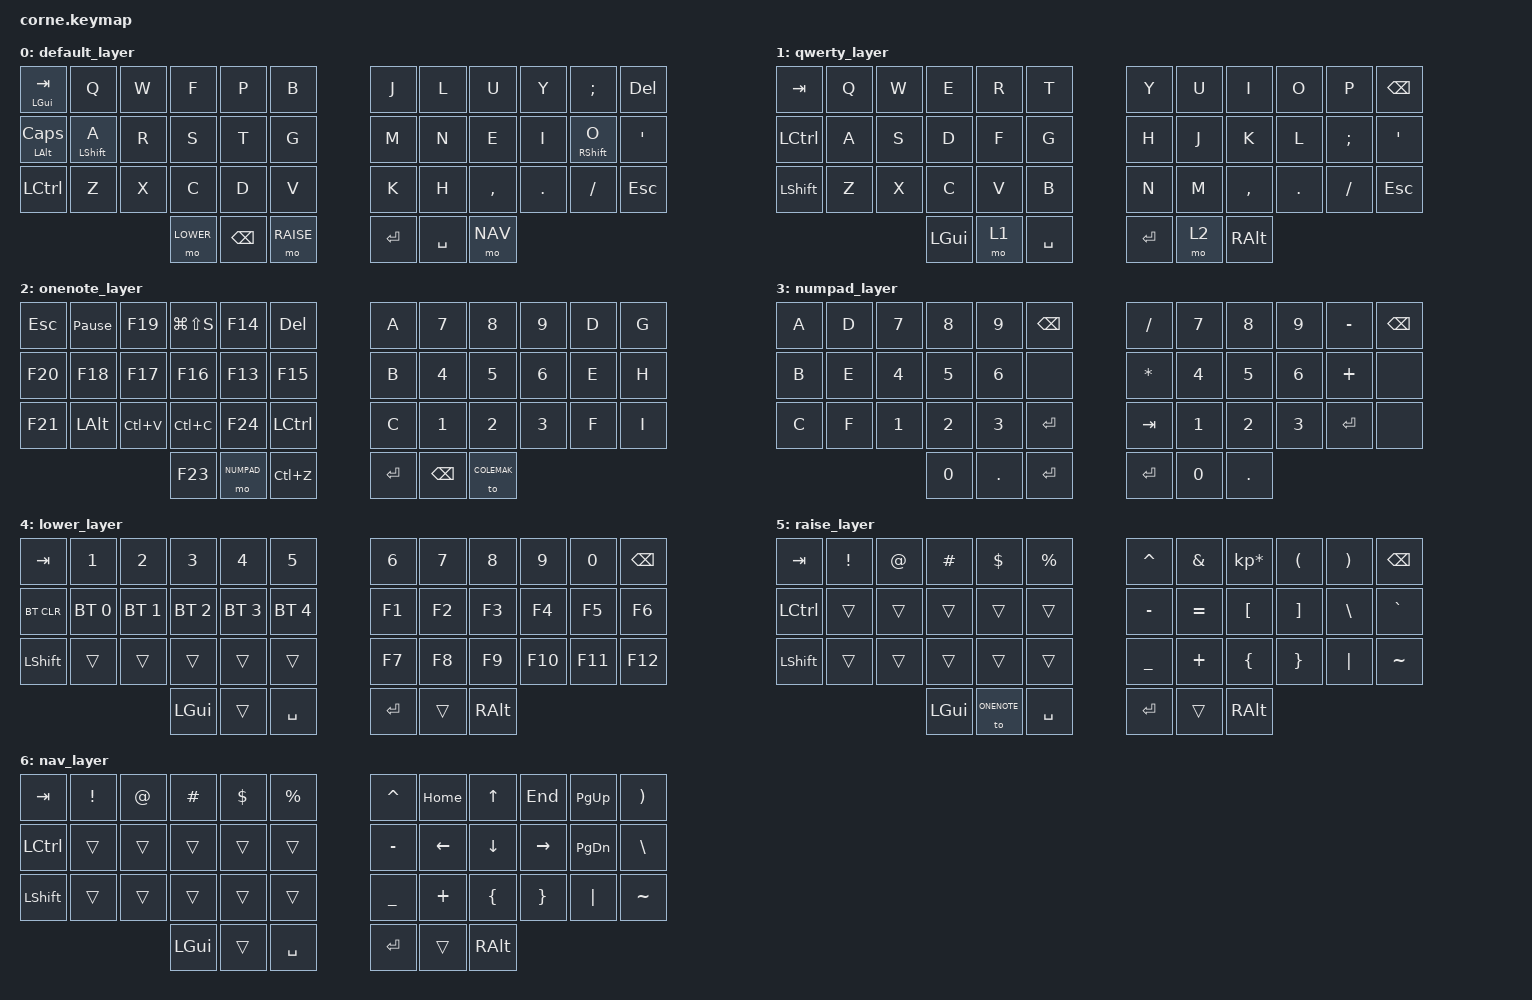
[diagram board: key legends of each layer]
/*
 * Copyright (c) 2020 The ZMK Contributors
 *
 * SPDX-License-Identifier: MIT
 */

#include <behaviors.dtsi>
#include <dt-bindings/zmk/keys.h>
#include <dt-bindings/zmk/bt.h>

#define COLEMAK 0
#define QWERTY  1
#define ONENOTE 2
#define NUMPAD  3
#define LOWER   4
#define RAISE   5
#define NAV		6



/ {
    combos {
        compatible = "zmk,combos";
		
		combo_colemak {
            timeout-ms = <50>;
            key-positions = <5 6 29 30>;
            bindings = <&to COLEMAK>;
        };
		
        combo_onenote {
            timeout-ms = <25>;
            key-positions = <0 24>;
            bindings = <&to ONENOTE>;
        };
		
		combo_qwerty {
			timeout-ms = <10>;
            key-positions = <1 10 25 34>;
            bindings = <&tog QWERTY>;
			layers = <COLEMAK>;
		};
		
		combo_numpad_L {
			timeout-ms = <25>;
            key-positions = <5 17>;
            bindings = <&tog NUMPAD>;
		};
		
		combo_numpad_R {
			timeout-ms = <25>;
            key-positions = <6 18>;
            bindings = <&tog NUMPAD>;
		};
    };
};

/ {
	behaviors {
		hm: homerow_mods {
			compatible = "zmk,behavior-hold-tap";
			label = "HOMEROW_MODS";
			#binding-cells = <2>;
			tapping-term-ms = <180>;
			quick_tap_ms = <125>;
			flavor = "balanced";
			bindings = <&kp>, <&kp>;
		};
	};

	keymap {
		compatible = "zmk,keymap";

		default_layer {
// -----------------------------------------------------------------------------------------
// | GUI/TAB  |    Q   |  W  |  F  |  P   |  B  |	|  J  |  L  |  U  |  Y  |   ;    | DEL |
// | ALT/CAPS | SHFT/A |  R  |  S  |  T   |  G  |	|  M  |  N  |  E  |  I  | SHFT/O |  '  |
// | CTRL     |    Z   |  X  |  C  |  D   |  V  |	|  K  |  H  |  ,  |  .  |   /    | ESC |
// 						     | LWR | BKSP | RSE |	| ENT | SPC | NAV |
			bindings = <
   &hm LGUI TAB  &kp Q 	     &kp W &kp F     &kp P    &kp B     &kp J   &kp L     &kp U     &kp Y   &kp SEMI	&kp DEL
   &hm LALT CAPS &hm LSHFT A &kp R &kp S     &kp T    &kp G     &kp M   &kp N     &kp E     &kp I   &hm RSHFT O &kp SQT
   &kp LCTRL     &kp Z		 &kp X &kp C	 &kp D    &kp V	    &kp K   &kp H     &kp COMMA &kp DOT &kp FSLH	&kp ESC
								   &mo LOWER &kp BSPC &mo RAISE &kp RET &kp SPACE &mo NAV
			>;
		};
				
		qwerty_layer {
// -----------------------------------------------------------------------------------------
// |  TAB |  Q  |  W  |  E  |  R  |  T  |   |  Y  |  U   |  I  |  O  |  P  | BKSP |
// | CTRL |  A  |  S  |  D  |  F  |  G  |   |  H  |  J   |  K  |  L  |  ;  |  '   |
// | SHFT |  Z  |  X  |  C  |  V  |  B  |   |  N  |  M   |  ,  |  .  |  /  | ESC  |
//                    | GUI | LWR | SPC |   | ENT | RSE  | ALT |
			bindings = <
   &kp TAB   &kp Q &kp W &kp E &kp R &kp T   &kp Y &kp U  &kp I     &kp O   &kp P    &kp BSPC
   &kp LCTRL &kp A &kp S &kp D &kp F &kp G   &kp H &kp J  &kp K     &kp L   &kp SEMI &kp SQT
   &kp LSHFT &kp Z &kp X &kp C &kp V &kp B   &kp N &kp M  &kp COMMA &kp DOT &kp FSLH &kp ESC
                  &kp LGUI &mo 1 &kp SPACE   &kp RET &mo 2 &kp RALT
			>;
		};
				
		onenote_layer {
// -----------------------------------------------------------------------------------------
// |  ESC  | MUTE |       | SNIP | ERSR   | DEL   |   |  a  |   7  |  8      |  9  |  d  |  g  |
// | PG UP |  RED | GREEN | BLUE | WHITE  | LASSO |   |  b  |   4  |  5      |  6  |  e  |  h  |
// | PG DN |  ALT | PASTE | COPY | PINK   | CTRL  |   |  c  |   1  |  2      |  3  |  f  |  i  |
//                        | NEW  | NUMPAD | UNDO  |   | ENT | BKSP | COLEMAK |
			bindings = <
   &kp ESC  &kp PAUSE_BREAK &kp F19		&kp LG(LS(S))&kp F14    &kp DEL		&kp A   &kp N7    &kp N8	  &kp N9 &kp D &kp G
   &kp F20 	&kp F18		 	&kp F17		&kp F16		 &kp F13    &kp F15		&kp B   &kp N4    &kp N5 	  &kp N6 &kp E &kp H
   &kp F21	&kp LALT		&kp LC(V)	&kp LC(C) 	 &kp F24    &kp LCTRL	&kp C   &kp N1	  &kp N2	  &kp N3 &kp F &kp I
										&kp F23		 &mo NUMPAD &kp LC(Z)	&kp RET &kp BSPC  &to COLEMAK
			>;
		};
				
		numpad_layer {
// -----------------------------------------------------------------------------------------
// | a | d |  7  |  8  |  9  | BKSP |   |  /  |  7  |  8  |  9  |  -  | BKSP |
// | b | e |  4  |  5  |  6  |      |   |  *  |  4  |  5  |  6  |  +  |      |
// | c | f |  1  |  2  |  3  | ENT  |   | TAB |  1  |  2  |  3  | ENT |      |
//               |  0  |  .  | ENT  |   | ENT |  0  |  .  |
			bindings = <
   &kp A &kp D &kp N7 &kp N8 &kp N9  &kp BSPC	&kp FSLH &kp N7 &kp N8 &kp N9 &kp MINUS &kp BSPC
   &kp B &kp E &kp N4 &kp N5 &kp N6  &none	    &kp STAR &kp N4 &kp N5 &kp N6 &kp PLUS  &none
   &kp C &kp F &kp N1 &kp N2 &kp N3  &kp RET	&kp TAB  &kp N1 &kp N2 &kp N3 &kp RET	&none
					  &kp N0 &kp DOT &kp RET    &kp RET  &kp N0 &kp DOT
			>;
		};
				
		lower_layer {
// -----------------------------------------------------------------------------------------
// |  TAB |  1  |  2  |  3  |  4  |  5  |   |  6  | 7  |  8  |  9  |  0  | BKSP |
// | BTCLR| BT1 | BT2 | BT3 | BT4 | BT5 |   | F1  | F2 | F3  | F4  | F5  |  F6  |
// | SHFT |     |     |     |     |     |   | F7  | F8 |  F9 | F10 | F11 |  F12 |
//                    | GUI |     | SPC |   | ENT |    | ALT |
			bindings = <
   &kp TAB    &kp N1       &kp N2       &kp N3       &kp N4       &kp N5         	&kp N6  &kp N7 &kp N8 &kp N9  &kp N0  &kp BSPC
   &bt BT_CLR &bt BT_SEL 0 &bt BT_SEL 1 &bt BT_SEL 2 &bt BT_SEL 3 &bt BT_SEL 4   	&kp F1  &kp F2 &kp F3 &kp F4  &kp F5  &kp F6
   &kp LSHFT  &trans       &trans       &trans       &trans       &trans         	&kp F7  &kp F8 &kp F9 &kp F10 &kp F11 &kp F12
										&kp LGUI     &trans       &kp SPACE      	&kp RET &trans &kp RALT
			>;
		};

		raise_layer {
// -----------------------------------------------------------------------------------------
// |  TAB |  !  |  @  |  #  |  $      |  %  |   |  ^  |  &  |  *  |  (  |  )  | BKSP |
// | CTRL |     |     |     |         |     |   |  -  |  =  |  [  |  ]  |  \  |  `   |
// | SHFT |     |     |     |         |     |   |  _  |  +  |  {  |  }  | "|" |  ~   |
//                    | GUI | ONENOTE | SPC |   | ENT |     | ALT |
			bindings = <
   &kp  TAB  &kp EXCL &kp AT &kp HASH &kp DLLR    &kp PRCNT   &kp CARET &kp AMPS  &kp KP_MULTIPLY &kp LPAR &kp RPAR &kp BSPC
   &kp LCTRL &trans   &trans &trans   &trans      &trans      &kp MINUS &kp EQUAL &kp LBKT        &kp RBKT &kp BSLH &kp GRAVE
   &kp LSHFT &trans   &trans &trans   &trans      &trans      &kp UNDER &kp PLUS  &kp LBRC        &kp RBRC &kp PIPE &kp TILDE
                    	     &kp LGUI &to ONENOTE &kp SPACE   &kp RET   &trans    &kp RALT
			>;
		};
				
		nav_layer {
// -----------------------------------------------------------------------------------------
// |   |     |     |     |     |     |   |    | HOME |  UP  | END | PG UP |    |
// |   |     |     |     |     |     |   |    | LEFT | DOWN | RGT | PG DN |    |
// |   |     |     |     |     |     |   |    |      |      |     |       |    |
//                 |     |     |     |   |    |      |      |
			bindings = <
   &kp  TAB  &kp EXCL &kp AT &kp HASH &kp DLLR &kp PRCNT   &kp CARET &kp HOME &kp UP   &kp END   &kp PG_UP &kp RPAR
   &kp LCTRL &trans   &trans &trans   &trans   &trans      &kp MINUS &kp LEFT &kp DOWN &kp RIGHT &kp PG_DN &kp BSLH
   &kp LSHFT &trans   &trans &trans   &trans   &trans      &kp UNDER &kp PLUS &kp LBRC &kp RBRC  &kp PIPE  &kp TILDE
                    	     &kp LGUI &trans   &kp SPACE   &kp RET   &trans    &kp RALT
			>;
		};
	};
};
